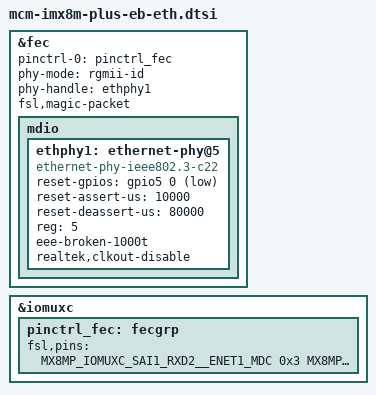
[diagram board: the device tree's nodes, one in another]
&fec {
	pinctrl-names = "default";
	pinctrl-0 = <&pinctrl_fec>;
	phy-mode = "rgmii-id";
	phy-handle = <&ethphy1>;
	fsl,magic-packet;
	status = "okay";

	mdio {
		#address-cells = <1>;
		#size-cells = <0>;

		ethphy1: ethernet-phy@5 {
			compatible = "ethernet-phy-ieee802.3-c22";
			reset-gpios = <&gpio5 0 GPIO_ACTIVE_LOW>;
			reset-assert-us = <10000>;
			reset-deassert-us = <80000>;
			reg = <5>;
			eee-broken-1000t;
			realtek,clkout-disable;
		};
	};
};

&iomuxc {
	pinctrl_fec: fecgrp {
		fsl,pins = <
			MX8MP_IOMUXC_SAI1_RXD2__ENET1_MDC		0x3
			MX8MP_IOMUXC_SAI1_RXD3__ENET1_MDIO		0x3
			MX8MP_IOMUXC_SAI1_RXD4__ENET1_RGMII_RD0		0x91
			MX8MP_IOMUXC_SAI1_RXD5__ENET1_RGMII_RD1		0x91
			MX8MP_IOMUXC_SAI1_RXD6__ENET1_RGMII_RD2		0x91
			MX8MP_IOMUXC_SAI1_RXD7__ENET1_RGMII_RD3		0x91
			MX8MP_IOMUXC_SAI1_TXC__ENET1_RGMII_RXC		0x91
			MX8MP_IOMUXC_SAI1_TXFS__ENET1_RGMII_RX_CTL	0x91
			MX8MP_IOMUXC_SAI1_TXD0__ENET1_RGMII_TD0		0x1f
			MX8MP_IOMUXC_SAI1_TXD1__ENET1_RGMII_TD1		0x1f
			MX8MP_IOMUXC_SAI1_TXD2__ENET1_RGMII_TD2		0x1f
			MX8MP_IOMUXC_SAI1_TXD3__ENET1_RGMII_TD3		0x1f
			MX8MP_IOMUXC_SAI1_TXD4__ENET1_RGMII_TX_CTL	0x1f
			MX8MP_IOMUXC_SAI1_TXD5__ENET1_RGMII_TXC		0x1f
			/* gpio */
			MX8MP_IOMUXC_GPIO1_IO05__GPIO1_IO05		0x19 /* WOL */
			MX8MP_IOMUXC_SAI3_TXFS__GPIO4_IO31 		0x19 /* INT */
			MX8MP_IOMUXC_SAI3_TXC__GPIO5_IO00 		0x19 /* RST */
		>;
	};
};

